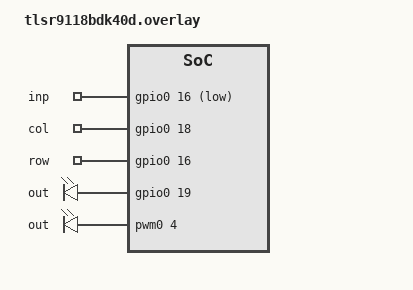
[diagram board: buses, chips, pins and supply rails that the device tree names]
/ {
	/* Short TL_Key1 (J20 pin 11) to ground (J20 pin 25-35) */
	key_pool {
		compatible = "gpio-keys";

		inp {
			gpios = <&gpio0 16 (GPIO_ACTIVE_LOW | GPIO_PULL_UP)>,
					<&gpio0 15 (GPIO_ACTIVE_LOW | GPIO_PULL_UP)>;
		};
	};

	key_matrix {
		compatible = "gpio-keys";

		col {
			gpios = <&gpio0 18 GPIO_ACTIVE_HIGH>,
					<&gpio0 17 GPIO_ACTIVE_HIGH>;
		};

		row {
			gpios = <&gpio0 16 (GPIO_PULL_DOWN | GPIO_ACTIVE_HIGH)>,
					<&gpio0 15 (GPIO_PULL_DOWN | GPIO_ACTIVE_HIGH)>;
		};
	};

	led_pool{
		compatible = "gpio-leds";

		out {
			gpios = <&gpio0 19 GPIO_ACTIVE_HIGH>;
		};
	};
	pwm_pool {
		compatible = "pwm-leds";
		out {
			pwms = <&pwm0 4 PWM_MSEC(1) PWM_POLARITY_NORMAL>,
				   <&pwm0 2 PWM_MSEC(1) PWM_POLARITY_NORMAL>,
				   <&pwm0 3 PWM_MSEC(1) PWM_POLARITY_NORMAL>;
		};
	};
};

&pwm0 {
	/* On board RGB LEDs */
	pinctrl-ch4 = <&pwm_ch4_p20_default>;
	pinctrl-ch2 = <&pwm_ch2_p17_default>;
	pinctrl-ch3 = <&pwm_ch3_p18_default>;
};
